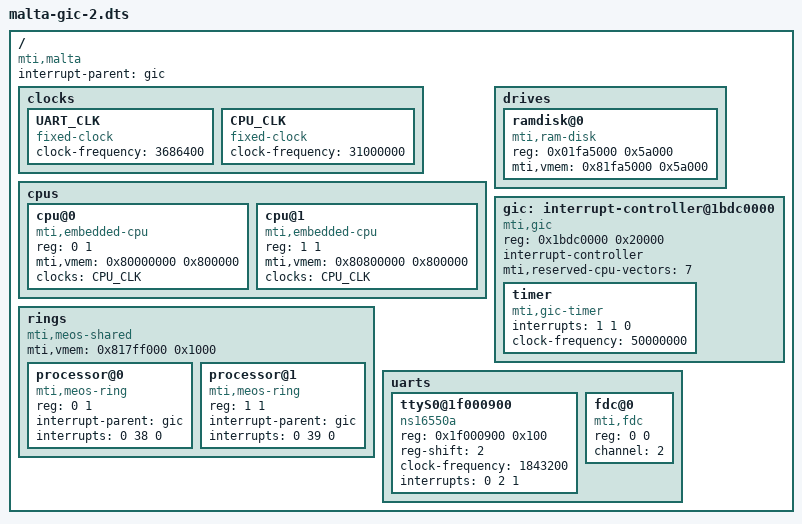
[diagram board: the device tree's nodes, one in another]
/dts-v1/;

/memreserve/ 0x00000000 0x00001000;	/* YAMON exception vectors */
/memreserve/ 0x00001000 0x000ef000;	/* YAMON */
/memreserve/ 0x000f0000 0x00010000;	/* PIIX4 ISA memory */

/ {
	#address-cells = <1>;
	#size-cells = <1>;
	compatible = "mti,malta";
	interrupt-parent = <&gic>;

	clocks {
		UART_CLK: UART_CLK {
			compatible = "fixed-clock";
			#clock-cells = <0>;
			clock-frequency = <3686400>;
		};
		CPU_CLK: CPU_CLK {
			compatible = "fixed-clock";
			#clock-cells = <0>;
			clock-frequency = <31000000>;
		};
	};

	cpus {
		#address-cells = <1>;
		#size-cells = <1>;

		cpu@0 {
			compatible = "mti,embedded-cpu", "mti,mips";
			reg = <0 1>;
			mti,vmem = <0x80000000 0x800000>;
			clocks = <&CPU_CLK>;
		};
		cpu@1 {
			compatible = "mti,embedded-cpu", "mti,mips";
			reg = <1 1>;
			mti,vmem = <0x80800000 0x800000>;
			clocks = <&CPU_CLK>;
		};
	};

	drives {
		#address-cells = <1>;
		#size-cells = <1>;
		ramdisk@0 {
			compatible = "mti,ram-disk";
			reg = <0x01fa5000 0x5a000>;
			mti,vmem = <0x81fa5000 0x5a000>;

		};
	};

	gic: interrupt-controller@1bdc0000 {
		compatible = "mti,gic";
		reg = <0x1bdc0000 0x20000>;

		interrupt-controller;
		#interrupt-cells = <3>;

		mti,reserved-cpu-vectors = <7>;


		timer {
			compatible = "mti,gic-timer";
			interrupts = <1 1 0>; /*<GIC_LOCAL 1 IRQ_TYPE_NONE>;*/
			clock-frequency = <50000000>;
		};
 	};

	rings {
		#address-cells = <1>;
		#size-cells = <1>;
		compatible = "mti,meos-shared";
		mti,vmem = <0x817ff000 0x1000>;

		processor@0 {
			compatible = "mti,meos-ring";
			reg = <0 1>;
			interrupt-parent = <&gic>;
			interrupts = <0 38 0>; /*<GIC_SHARED 38 IRQ_TYPE_NONE>;*/
		};

		processor@1 {
			compatible = "mti,meos-ring";
			reg = <1 1>;
			interrupt-parent = <&gic>;
			interrupts = <0 39 0>; /*<GIC_SHARED 39 IRQ_TYPE_NONE>;*/
		};
	};

	uarts {
		#address-cells = <1>;
		#size-cells = <1>;
		ttyS0@1f000900 {
			compatible = "ns16550a";
			reg = <0x1f000900 0x100>;
			reg-shift = <2>;
			clock-frequency = <1843200>;
			interrupts = <0 2 1>;
		};
		fdc@0 {
			compatible = "mti,fdc";
			reg = <0 0>;
			channel = <2>;
		};
	};
};
